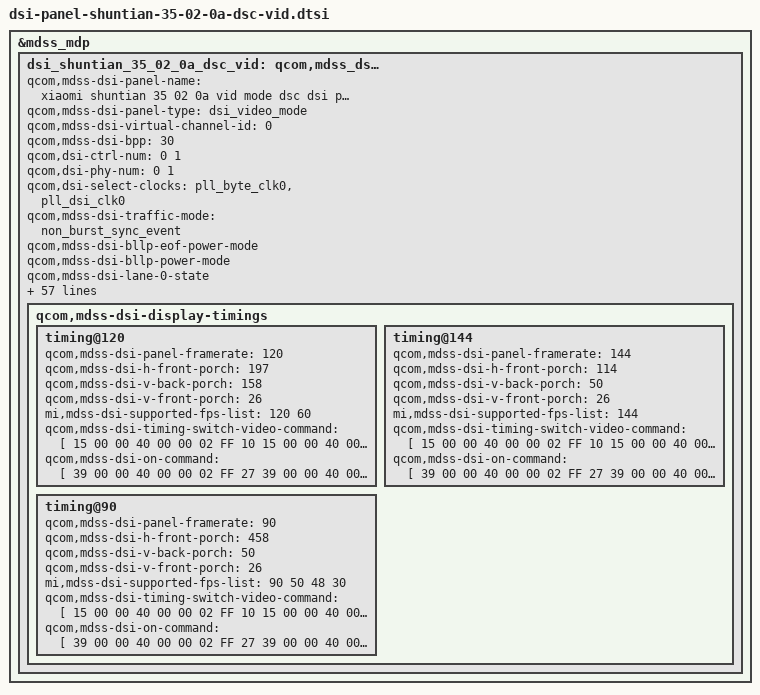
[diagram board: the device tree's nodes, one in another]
&mdss_mdp {
	dsi_shuntian_35_02_0a_dsc_vid: qcom,mdss_dsi_shuntian_35_02_0a_dsc_vid {
		qcom,mdss-dsi-panel-name = "xiaomi shuntian 35 02 0a vid mode dsc dsi panel";
		qcom,mdss-dsi-panel-type = "dsi_video_mode";
		qcom,mdss-dsi-virtual-channel-id = <0>;
		qcom,mdss-dsi-bpp = <30>;
		qcom,dsi-ctrl-num = <0 1>;
		qcom,dsi-phy-num = <0 1>;
		qcom,dsi-select-clocks = "pll_byte_clk0", "pll_dsi_clk0";
		qcom,mdss-dsi-traffic-mode = "non_burst_sync_event";
		qcom,mdss-dsi-bllp-eof-power-mode;
		qcom,mdss-dsi-bllp-power-mode;
		qcom,mdss-dsi-lane-0-state;
		qcom,mdss-dsi-lane-1-state;
		qcom,mdss-dsi-lane-2-state;
		qcom,mdss-dsi-lane-3-state;
		qcom,mdss-dsi-color-order = "rgb_swap_rgb";
		qcom,mdss-dsi-dma-trigger = "trigger_sw";
		qcom,mdss-dsi-mdp-trigger = "none";
		qcom,mdss-dsi-reset-sequence =<0 10>, <1 3>, <0 3>, <1 15>;
		qcom,mdss-pan-physical-width-dimension = <2640>;
		qcom,mdss-pan-physical-height-dimension = <1762>;
		qcom,mdss-dsi-te-pin-select = <1>;
		qcom,mdss-dsi-te-dcs-command = <1>;
		qcom,mdss-dsi-tx-eot-append;
		qcom,mdss-dsi-lp11-init;
		qcom,mdss-dsi-bl-inverted-dbv;
		qcom,bl-update-flag = "delay_until_first_frame";
		qcom,mdss-dsi-panel-hdr-enabled;
		qcom,mdss-dsi-panel-hdr-color-primaries = <14500 15500 32000
			17000 15500 30000 8000 3000>;
		qcom,mdss-dsi-panel-peak-brightness = <10000000>;
		qcom,mdss-dsi-panel-blackness-level = <7000>;
		qcom,mdss-dsi-bl-min-level = <4>;
		qcom,mdss-dsi-bl-max-level = <4095>;
		qcom,mdss-brightness-max-level = <4095>;
		qcom,mdss-brightness-init-level = <307>;

		qcom,mdss-disable-cesta-hw-sleep;
		qcom,mdss-dsi-stream = <0>;
		qcom,mdss-dsi-underflow-color = <0xff>;
		qcom,mdss-dsi-border-color = <0>;
		qcom,adjust-timer-wakeup-ms = <1>;
		qcom,mdss-dsi-rx-eot-ignore;
		qcom,cmd-sync-wait-broadcast;
		qcom,mdss-dsi-panel-broadcast-mode;

		qcom,mdss-dsi-pan-enable-dynamic-fps;
		qcom,mdss-dsi-pan-fps-update = "dfps_immediate_porch_mode_vfp";
		qcom,dsi-supported-dfps-list = <120 144 90 60 50 48 30>;

		qcom,mdss-dsi-display-timings {
			timing@120{
				#include "dsi-panel-shuntian-35-02-0a-dsc-vid-common.dtsi"
				qcom,mdss-dsi-panel-framerate = <120>;
				qcom,mdss-dsi-h-front-porch = <197>;
				qcom,mdss-dsi-v-back-porch = <158>;
				qcom,mdss-dsi-v-front-porch = <26>;
				mi,mdss-dsi-supported-fps-list = <120 60>;
				qcom,mdss-dsi-timing-switch-video-command = [
					15 00 00 40 00 00 02 FF 10
					15 00 00 40 00 00 02 FB 01
					15 00 00 00 00 00 02 B3 40
				];
				qcom,mdss-dsi-on-command= [
					//ESD
					39 00 00 40 00 00 02 FF 27
					39 00 00 40 00 00 02 FB 01
					39 00 00 40 00 00 02 D0 31
					39 00 00 40 00 00 03 D1 02 00
					39 00 00 40 00 00 02 D2 03
					39 00 00 40 00 00 02 D3 10
					39 00 00 40 00 00 02 D4 00
					39 00 00 40 00 00 02 DE 43
					39 00 00 00 00 00 02 DF 02
					//CABC start
					39 00 00 40 00 00 02 FF 23
					39 00 00 40 00 00 02 FB 01
					39 00 00 40 00 00 02 00 80
					39 00 00 40 00 00 02 01 84
					39 00 00 40 00 00 02 05 2D
					39 00 00 40 00 00 02 06 00
					39 00 00 40 00 00 02 11 04
					39 00 00 40 00 00 02 12 2C
					39 00 00 40 00 00 02 15 9E
					39 00 00 40 00 00 02 16 16
					//UI mode
					39 00 00 40 00 00 02 29 0A
					39 00 00 40 00 00 02 30 FF
					39 00 00 40 00 00 02 31 FE
					39 00 00 40 00 00 02 32 FD
					39 00 00 40 00 00 02 33 FB
					39 00 00 40 00 00 02 34 F8
					39 00 00 40 00 00 02 35 F5
					39 00 00 40 00 00 02 36 F3
					39 00 00 40 00 00 02 37 F2
					39 00 00 40 00 00 02 38 F2
					39 00 00 40 00 00 02 39 F2
					39 00 00 40 00 00 02 3A EF
					39 00 00 40 00 00 02 3B EC
					39 00 00 40 00 00 02 3D E9
					39 00 00 40 00 00 02 3F E5
					39 00 00 40 00 00 02 40 E5
					39 00 00 40 00 00 02 41 E5
					//STILL mode
					39 00 00 40 00 00 02 2A 13
					39 00 00 40 00 00 02 45 FF
					39 00 00 40 00 00 02 46 F4
					39 00 00 40 00 00 02 47 E7
					39 00 00 40 00 00 02 48 DA
					39 00 00 40 00 00 02 49 CD
					39 00 00 40 00 00 02 4A C0
					39 00 00 40 00 00 02 4B B3
					39 00 00 40 00 00 02 4C B1
					39 00 00 40 00 00 02 4D B1
					39 00 00 40 00 00 02 4E B1
					39 00 00 40 00 00 02 4F 95
					39 00 00 40 00 00 02 50 79
					39 00 00 40 00 00 02 51 5C
					39 00 00 40 00 00 02 52 58
					39 00 00 40 00 00 02 53 58
					39 00 00 40 00 00 02 54 58
					//MOVING mode
					39 00 00 40 00 00 02 2B 0E
					39 00 00 40 00 00 02 58 FF
					39 00 00 40 00 00 02 59 FB
					39 00 00 40 00 00 02 5A F7
					39 00 00 40 00 00 02 5B F3
					39 00 00 40 00 00 02 5C EF
					39 00 00 40 00 00 02 5D E3
					39 00 00 40 00 00 02 5E D8
					39 00 00 40 00 00 02 5F D6
					39 00 00 40 00 00 02 60 D6
					39 00 00 40 00 00 02 61 D6
					39 00 00 40 00 00 02 62 C8
					39 00 00 40 00 00 02 63 B7
					39 00 00 40 00 00 02 64 AA
					39 00 00 40 00 00 02 65 A8
					39 00 00 40 00 00 02 66 A8
					39 00 00 40 00 00 02 67 A8
					39 00 00 40 00 00 02 6F 04
					//open PWM for CABC
					39 00 00 40 00 00 02 FF 10
					39 00 00 40 00 00 02 FB 01
					39 00 00 40 00 00 03 51 0F FF
					39 00 00 00 00 00 02 53 2C
					//CABC end
					39 00 00 40 00 00 02 FF 23
					39 00 00 40 00 00 02 FB 01
					39 00 00 40 00 00 02 89 A4
					39 00 00 40 00 00 02 8B C1
					39 00 00 40 00 00 02 FF E0
					39 00 00 40 00 00 02 FB 01
					39 00 00 40 00 00 02 BB 00
					39 00 00 40 00 00 02 FF F0
					39 00 00 40 00 00 02 FB 01
					39 00 00 40 00 00 02 E6 02
					39 00 00 40 00 00 02 FF 22
					39 00 00 40 00 00 02 FB 01
					39 00 00 40 00 00 02 B8 03
					39 00 00 40 00 00 02 A6 07
					39 00 00 40 00 00 02 FF 27
					39 00 00 40 00 00 02 FB 01
					39 00 00 40 00 00 02 04 00
					39 00 00 40 00 00 02 05 F0
					39 00 00 40 00 00 02 06 22
					39 00 00 40 00 00 02 07 03
					39 00 00 40 00 00 03 08 C0 08
					39 00 00 40 00 00 02 FF 20
					39 00 00 40 00 00 02 FB 01
					39 00 00 40 00 00 02 58 03
					39 00 00 40 00 00 02 FF 10
					39 00 00 40 00 00 02 FB 01
					39 00 00 40 00 00 0A 3B 03 A2 1A 04 04 00 80 36 36
					39 00 00 40 00 00 02 60 00
					39 00 00 40 00 00 03 90 03 00
					39 00 00 40 00 00 11 91 AB A8 00 18 D2 00 00 00 02 9F 00 0B 04 86 02 DC
					39 00 00 40 00 00 03 92 10 F0
					39 00 00 40 00 00 03 B2 91 80
					39 00 00 00 00 00 02 B3 40
					39 00 00 00 78 00 02 11 00
					39 00 00 00 00 00 02 29 00
				];
			};
			timing@144{
				#include "dsi-panel-shuntian-35-02-0a-dsc-vid-common.dtsi"
				qcom,mdss-dsi-panel-framerate = <144>;
				qcom,mdss-dsi-h-front-porch = <114>;
				qcom,mdss-dsi-v-back-porch = <50>;
				qcom,mdss-dsi-v-front-porch = <26>;
				mi,mdss-dsi-supported-fps-list = <144>;
				qcom,mdss-dsi-timing-switch-video-command = [
					15 00 00 40 00 00 02 FF 10
					15 00 00 40 00 00 02 FB 01
					15 00 00 00 00 00 02 B3 00
				];
				qcom,mdss-dsi-on-command= [
					//ESD
					39 00 00 40 00 00 02 FF 27
					39 00 00 40 00 00 02 FB 01
					39 00 00 40 00 00 02 D0 31
					39 00 00 40 00 00 03 D1 02 00
					39 00 00 40 00 00 02 D2 03
					39 00 00 40 00 00 02 D3 10
					39 00 00 40 00 00 02 D4 00
					39 00 00 40 00 00 02 DE 43
					39 00 00 00 00 00 02 DF 02
					//CABC start
					39 00 00 40 00 00 02 FF 23
					39 00 00 40 00 00 02 FB 01
					39 00 00 40 00 00 02 00 80
					39 00 00 40 00 00 02 01 84
					39 00 00 40 00 00 02 05 2D
					39 00 00 40 00 00 02 06 00
					39 00 00 40 00 00 02 11 04
					39 00 00 40 00 00 02 12 2C
					39 00 00 40 00 00 02 15 9E
					39 00 00 40 00 00 02 16 16
					//UI mode
					39 00 00 40 00 00 02 29 0A
					39 00 00 40 00 00 02 30 FF
					39 00 00 40 00 00 02 31 FE
					39 00 00 40 00 00 02 32 FD
					39 00 00 40 00 00 02 33 FB
					39 00 00 40 00 00 02 34 F8
					39 00 00 40 00 00 02 35 F5
					39 00 00 40 00 00 02 36 F3
					39 00 00 40 00 00 02 37 F2
					39 00 00 40 00 00 02 38 F2
					39 00 00 40 00 00 02 39 F2
					39 00 00 40 00 00 02 3A EF
					39 00 00 40 00 00 02 3B EC
					39 00 00 40 00 00 02 3D E9
					39 00 00 40 00 00 02 3F E5
					39 00 00 40 00 00 02 40 E5
					39 00 00 40 00 00 02 41 E5
					//STILL mode
					39 00 00 40 00 00 02 2A 13
					39 00 00 40 00 00 02 45 FF
					39 00 00 40 00 00 02 46 F4
					39 00 00 40 00 00 02 47 E7
					39 00 00 40 00 00 02 48 DA
					39 00 00 40 00 00 02 49 CD
					39 00 00 40 00 00 02 4A C0
					39 00 00 40 00 00 02 4B B3
					39 00 00 40 00 00 02 4C B1
					39 00 00 40 00 00 02 4D B1
					39 00 00 40 00 00 02 4E B1
					39 00 00 40 00 00 02 4F 95
					39 00 00 40 00 00 02 50 79
					39 00 00 40 00 00 02 51 5C
					39 00 00 40 00 00 02 52 58
					39 00 00 40 00 00 02 53 58
					39 00 00 40 00 00 02 54 58
					//MOVING mode
					39 00 00 40 00 00 02 2B 0E
					39 00 00 40 00 00 02 58 FF
					39 00 00 40 00 00 02 59 FB
					39 00 00 40 00 00 02 5A F7
					39 00 00 40 00 00 02 5B F3
					39 00 00 40 00 00 02 5C EF
					39 00 00 40 00 00 02 5D E3
					39 00 00 40 00 00 02 5E D8
					39 00 00 40 00 00 02 5F D6
					39 00 00 40 00 00 02 60 D6
					39 00 00 40 00 00 02 61 D6
					39 00 00 40 00 00 02 62 C8
					39 00 00 40 00 00 02 63 B7
					39 00 00 40 00 00 02 64 AA
					39 00 00 40 00 00 02 65 A8
					39 00 00 40 00 00 02 66 A8
					39 00 00 40 00 00 02 67 A8
					39 00 00 40 00 00 02 6F 04
					//open PWM for CABC
					39 00 00 40 00 00 02 FF 10
					39 00 00 40 00 00 02 FB 01
					39 00 00 40 00 00 03 51 0F FF
					39 00 00 00 00 00 02 53 2C
					//CABC end
					39 00 00 40 00 00 02 FF 23
					39 00 00 40 00 00 02 FB 01
					39 00 00 40 00 00 02 89 A4
					39 00 00 40 00 00 02 8B C1
					39 00 00 40 00 00 02 FF E0
					39 00 00 40 00 00 02 FB 01
					39 00 00 40 00 00 02 BB 00
					39 00 00 40 00 00 02 FF F0
					39 00 00 40 00 00 02 FB 01
					39 00 00 40 00 00 02 E6 02
					39 00 00 40 00 00 02 FF 22
					39 00 00 40 00 00 02 FB 01
					39 00 00 40 00 00 02 B8 03
					39 00 00 40 00 00 02 A6 07
					39 00 00 40 00 00 02 FF 27
					39 00 00 40 00 00 02 FB 01
					39 00 00 40 00 00 02 04 00
					39 00 00 40 00 00 02 05 F0
					39 00 00 40 00 00 02 06 22
					39 00 00 40 00 00 02 07 03
					39 00 00 40 00 00 03 08 C0 08
					39 00 00 40 00 00 02 FF 20
					39 00 00 40 00 00 02 FB 01
					39 00 00 40 00 00 02 58 03
					39 00 00 40 00 00 02 FF 10
					39 00 00 40 00 00 02 FB 01
					39 00 00 40 00 00 0A 3B 03 A2 1A 04 04 00 80 36 36
					39 00 00 40 00 00 02 60 00
					39 00 00 40 00 00 03 90 03 00
					39 00 00 40 00 00 11 91 AB A8 00 18 D2 00 00 00 02 9F 00 0B 04 86 02 DC
					39 00 00 40 00 00 03 92 10 F0
					39 00 00 40 00 00 03 B2 91 80
					39 00 00 00 00 00 02 B3 00
					39 00 00 00 78 00 02 11 00
					39 00 00 00 00 00 02 29 00
				];
			};
			timing@90{
				#include "dsi-panel-shuntian-35-02-0a-dsc-vid-common.dtsi"
				qcom,mdss-dsi-panel-framerate = <90>;
				qcom,mdss-dsi-h-front-porch = <458>;
				qcom,mdss-dsi-v-back-porch = <50>;
				qcom,mdss-dsi-v-front-porch = <26>;
				mi,mdss-dsi-supported-fps-list = <90 50 48 30>;
				qcom,mdss-dsi-timing-switch-video-command = [
					15 00 00 40 00 00 02 FF 10
					15 00 00 40 00 00 02 FB 01
					15 00 00 00 00 00 02 B3 80
				];
			qcom,mdss-dsi-on-command= [
					//ESD
					39 00 00 40 00 00 02 FF 27
					39 00 00 40 00 00 02 FB 01
					39 00 00 40 00 00 02 D0 31
					39 00 00 40 00 00 03 D1 02 00
					39 00 00 40 00 00 02 D2 03
					39 00 00 40 00 00 02 D3 10
					39 00 00 40 00 00 02 D4 00
					39 00 00 40 00 00 02 DE 43
					39 00 00 00 00 00 02 DF 02
					//CABC start
					39 00 00 40 00 00 02 FF 23
					39 00 00 40 00 00 02 FB 01
					39 00 00 40 00 00 02 00 80
					39 00 00 40 00 00 02 01 84
					39 00 00 40 00 00 02 05 2D
					39 00 00 40 00 00 02 06 00
					39 00 00 40 00 00 02 11 04
					39 00 00 40 00 00 02 12 2C
					39 00 00 40 00 00 02 15 9E
					39 00 00 40 00 00 02 16 16
					//UI mode
					39 00 00 40 00 00 02 29 0A
					39 00 00 40 00 00 02 30 FF
					39 00 00 40 00 00 02 31 FE
					39 00 00 40 00 00 02 32 FD
					39 00 00 40 00 00 02 33 FB
					39 00 00 40 00 00 02 34 F8
					39 00 00 40 00 00 02 35 F5
					39 00 00 40 00 00 02 36 F3
					39 00 00 40 00 00 02 37 F2
					39 00 00 40 00 00 02 38 F2
					39 00 00 40 00 00 02 39 F2
					39 00 00 40 00 00 02 3A EF
					39 00 00 40 00 00 02 3B EC
					39 00 00 40 00 00 02 3D E9
					39 00 00 40 00 00 02 3F E5
					39 00 00 40 00 00 02 40 E5
					39 00 00 40 00 00 02 41 E5
					//STILL mode
					39 00 00 40 00 00 02 2A 13
					39 00 00 40 00 00 02 45 FF
					39 00 00 40 00 00 02 46 F4
					39 00 00 40 00 00 02 47 E7
					39 00 00 40 00 00 02 48 DA
					39 00 00 40 00 00 02 49 CD
					39 00 00 40 00 00 02 4A C0
					39 00 00 40 00 00 02 4B B3
					39 00 00 40 00 00 02 4C B1
					39 00 00 40 00 00 02 4D B1
					39 00 00 40 00 00 02 4E B1
					39 00 00 40 00 00 02 4F 95
					39 00 00 40 00 00 02 50 79
					39 00 00 40 00 00 02 51 5C
					39 00 00 40 00 00 02 52 58
					39 00 00 40 00 00 02 53 58
					39 00 00 40 00 00 02 54 58
					//MOVING mode
					39 00 00 40 00 00 02 2B 0E
					39 00 00 40 00 00 02 58 FF
					39 00 00 40 00 00 02 59 FB
					39 00 00 40 00 00 02 5A F7
					39 00 00 40 00 00 02 5B F3
					39 00 00 40 00 00 02 5C EF
					39 00 00 40 00 00 02 5D E3
					39 00 00 40 00 00 02 5E D8
					39 00 00 40 00 00 02 5F D6
					39 00 00 40 00 00 02 60 D6
					39 00 00 40 00 00 02 61 D6
					39 00 00 40 00 00 02 62 C8
					39 00 00 40 00 00 02 63 B7
					39 00 00 40 00 00 02 64 AA
					39 00 00 40 00 00 02 65 A8
					39 00 00 40 00 00 02 66 A8
					39 00 00 40 00 00 02 67 A8
					39 00 00 40 00 00 02 6F 04
					//open PWM for CABC
					39 00 00 40 00 00 02 FF 10
					39 00 00 40 00 00 02 FB 01
					39 00 00 40 00 00 03 51 0F FF
					39 00 00 00 00 00 02 53 2C
					//CABC end
					39 00 00 40 00 00 02 FF 23
					39 00 00 40 00 00 02 FB 01
					39 00 00 40 00 00 02 89 A4
					39 00 00 40 00 00 02 8B C1
					39 00 00 40 00 00 02 FF E0
					39 00 00 40 00 00 02 FB 01
					39 00 00 40 00 00 02 BB 00
					39 00 00 40 00 00 02 FF F0
					39 00 00 40 00 00 02 FB 01
					39 00 00 40 00 00 02 E6 02
					39 00 00 40 00 00 02 FF 22
					39 00 00 40 00 00 02 FB 01
					39 00 00 40 00 00 02 B8 03
					39 00 00 40 00 00 02 A6 07
					39 00 00 40 00 00 02 FF 27
					39 00 00 40 00 00 02 FB 01
					39 00 00 40 00 00 02 04 00
					39 00 00 40 00 00 02 05 F0
					39 00 00 40 00 00 02 06 22
					39 00 00 40 00 00 02 07 03
					39 00 00 40 00 00 03 08 C0 08
					39 00 00 40 00 00 02 FF 20
					39 00 00 40 00 00 02 FB 01
					39 00 00 40 00 00 02 58 03
					39 00 00 40 00 00 02 FF 10
					39 00 00 40 00 00 02 FB 01
					39 00 00 40 00 00 0A 3B 03 A2 1A 04 04 00 80 36 36
					39 00 00 40 00 00 02 60 00
					39 00 00 40 00 00 03 90 03 00
					39 00 00 40 00 00 11 91 AB A8 00 18 D2 00 00 00 02 9F 00 0B 04 86 02 DC
					39 00 00 40 00 00 03 92 10 F0
					39 00 00 40 00 00 03 B2 91 80
					39 00 00 00 00 00 02 B3 80
					39 00 00 00 78 00 02 11 00
					39 00 00 00 00 00 02 29 00
				];
			};
		};
	};
};
&dsi_shuntian_35_02_0a_dsc_vid {
	qcom,platform-reset-gpio = <&tlmm 146 0>;
	mi,panel-nt336-ason08-gpio  = <&tlmm 212 0>;
	mi,panel-nt336-ason18-gpio  = <&tlmm 214 0>;
	mi,max-brightness-clone = <4095>;
	mi,max-brightness-normal = <4095>;
	mi,mdss-dsi-fac-bl-max-level = <2047>;
	mi,mdss-fac-brightness-max-level = <2047>;
	mi,panel-on-dimming-delay = <120>;

	//mi,mdss-dsi-panel-wp-read-command = [06 01 00 01 00 00 01 5C];
	//mi,mdss-dsi-panel-wp-read-command-state = "dsi_hs_mode";
	//mi,mdss-dsi-panel-wp-read-length = <8>;

	//mi,mdss-dsi-panel-cell-id-read-command = [06 01 00 01 00 00 01 5A];
	//mi,mdss-dsi-panel-cell-id-read-command-state = "dsi_hs_mode";
	//mi,mdss-dsi-panel-cell-id-read-length = <14>;

	//mi,panel-build-id-read-needed;
	//mi,panel-build-id-read-length = <1>;
	//mi,mdss-dsi-panel-build-id-read-command = [06 01 00 01 00 00 01 DA];
	//mi,mdss-dsi-panel-build-id-read-command-state = "dsi_hs_mode";

	qcom,mdss-dsi-clk-strength = <0xFF>;
	mi,panel-id = <0x5348554E 0x0035020A>;
	mi,feature-enabled;
	mi,is-tddi-flag;
	mi,mdss-panel-on-dimming-delay = <300>;
	mi,esd-err-irq-gpio = <&tlmm 87 0x2004>; /* trig-flags: falling-0x0002 rasing-0x0001*/
	mi,esd-err-irq-gpio-flag = <0x2004>;
	mi,esd-err-irq-gpio-second = <&tlmm 88 0x2004>; /* trig-flags: falling-0x0002 rasing-0x0001*/
	mi,esd-err-irq-gpio-flag-second = <0x2004>;
	//mi,mdss-dsi-panel-xy-coordinate = <0x6 0x18>;
	//mi,mdss-dsi-panel-max-luminance = <0x6 0x4>;
	mi,thermal-dimming-flag;
	mi,video-mode-multi-timing;
};
